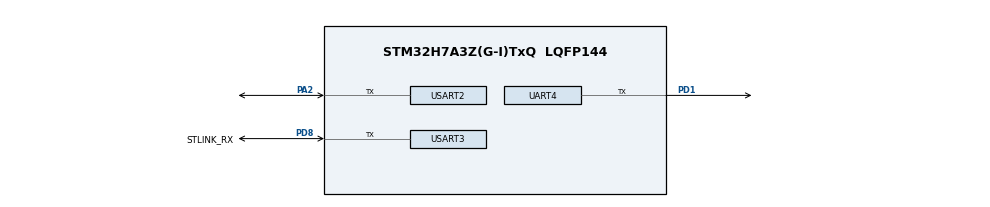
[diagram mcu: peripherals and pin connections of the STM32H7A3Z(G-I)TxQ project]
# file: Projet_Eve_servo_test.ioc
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Mcu.Family=STM32H7
Mcu.Name=STM32H7A3Z(G-I)TxQ
Mcu.Package=LQFP144
NVIC.PriorityGroup=NVIC_PRIORITYGROUP_4
PA2.GPIO_ModeDefaultOD=GPIO_MODE_AF_PP
PA2.GPIO_PuPd=GPIO_PULLUP
PA2.Mode=Half_duplex(single_wire_mode)
PA2.Signal=USART2_TX
PC14-OSC32_IN.GPIO_Label=OSC32_IN
PC14-OSC32_IN.Mode=LSE-External-Oscillator
PC14-OSC32_IN.Signal=RCC_OSC32_IN
PC15-OSC32_OUT.GPIO_Label=OSC32_OUT
PC15-OSC32_OUT.Mode=LSE-External-Oscillator
PC15-OSC32_OUT.Signal=RCC_OSC32_OUT
PD1.GPIO_ModeDefaultOD=GPIO_MODE_AF_OD
PD1.GPIO_PuPd=GPIO_PULLUP
PD1.GPIO_Speed=GPIO_SPEED_FREQ_VERY_HIGH
PD1.Mode=Half_duplex(single_wire_mode)
PD1.Signal=UART4_TX
PD8.GPIO_Label=STLINK_RX
PD8.GPIO_ModeDefaultOD=GPIO_MODE_AF_OD
PD8.GPIO_PuPd=GPIO_PULLUP
PD8.GPIO_Speed=GPIO_SPEED_FREQ_VERY_HIGH
PD8.Mode=Half_duplex(single_wire_mode)
PD8.Signal=USART3_TX
PD9.GPIO_Label=STLINK_TX
PD9.Signal=USART3_RX
PH0-OSC_IN.GPIO_Label=PH0-MCU
PH0-OSC_IN.Mode=HSE-External-Clock-Source
PH0-OSC_IN.Signal=RCC_OSC_IN
ProjectManager.HeapSize=0x200
ProjectManager.StackSize=0x400
ProjectManager.TargetToolchain=STM32CubeIDE
RCC.ADCFreq_Value=16125000
RCC.APB1Freq_Value=96000000
RCC.APB2Freq_Value=96000000
RCC.APB3Freq_Value=96000000
RCC.APB4Freq_Value=96000000
RCC.CortexFreq_Value=96000000
RCC.DIVM1=1
RCC.DIVM3=1
RCC.DIVN1=24
RCC.DIVN3=24
RCC.DIVQ1=4
RCC.HCLKFreq_Value=96000000
RCC.HSE_VALUE=8000000
RCC.PLLFRACN=0
RCC.PLLSourceVirtual=RCC_PLLSOURCE_HSE
RCC.PWR_Regulator_Voltage_Scale=PWR_REGULATOR_VOLTAGE_SCALE0
RCC.SYSCLKFreq_VALUE=96000000
RCC.SYSCLKSource=RCC_SYSCLKSOURCE_PLLCLK
RCC.SupplySource=PWR_DIRECT_SMPS_SUPPLY
RCC.USBCLockSelection=RCC_USBCLKSOURCE_HSI48
RCC.USBFreq_Value=48000000
UART4.BaudRate=57600
UART4.Mode=MODE_TX
USART2.BaudRate=57600
USART2.VirtualMode-Half_duplex(single_wire_mode)=VM_ASYNC
USART3.Mode=MODE_TX_RX
USART3.VirtualMode-Half_duplex(single_wire_mode)=VM_ASYNC
board=NUCLEO-H7A3ZI-Q

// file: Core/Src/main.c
/* USER CODE BEGIN Header */
/**
  ******************************************************************************
  * @file           : main.c
  * @brief          : Main program body
  ******************************************************************************
  * @attention
  *
  * Copyright (c) 2023 STMicroelectronics.
  * All rights reserved.
  *
  * This software is licensed under terms that can be found in the LICENSE file
  * in the root directory of this software component.
  * If no LICENSE file comes with this software, it is provided AS-IS.
  *
  ******************************************************************************
  */
/* USER CODE END Header */
#include "main.h"
#include "usart.h"
#include "gpio.h"

/* USER CODE BEGIN Includes */
#include <stdio.h>
#include <string.h>
#include <stdint.h>
#include "stm32h7xx.h"
#include "dyn2.h"
#include "constants.h"

/* USER CODE END Includes */

void SystemClock_Config(void);

int main(void)
{

  /* MCU Configuration--------------------------------------------------------*/

  /* Reset of all peripherals, Initializes the Flash interface and the Systick. */
  HAL_Init();

  /* Configure the system clock */
  SystemClock_Config();

  /* Initialize all configured peripherals */
  MX_GPIO_Init();
  MX_USART3_UART_Init();
  MX_UART4_Init();
  MX_USART2_UART_Init();
  /* USER CODE BEGIN 2 */

  MOTOR XL430_1 = {
      .model = XL430,
      .baudrate = 57600,
      .uart = huart4, // Assuming huart4 is already defined elsewhere
      .id = 1
  };

  MOTOR XL320_1 = {
      .model = XL320,
      .baudrate = 1000000,
      .uart = huart4, // Assuming huart4 is already defined elsewhere
      .id = 0xFE
  };
  //dyn2_torque(XL320_1, TORQUE_ON);
  //float angle = 0;
//  for(int i = 0;i<10;i++){
//	  dyn2_led(XL320_1,2);
//	  //dyn2_torque(XL320_1, TORQUE_ON);
//	  dyn2_position(XL320_1, angle);
//	  HAL_Delay(2000);
//	  dyn2_led(XL320_1,0);
//	  HAL_Delay(2000);
//	  angle +=45;
//
//
//  }
  	 dyn2_led(XL320_1, 2);
  	 //dyn2_torque(XL320_1, TORQUE_OFF);
  	 //dyn2_baudrate(XL320_1, 1);

  /* USER CODE END 2 */

  /* Infinite loop */
  /* USER CODE BEGIN WHILE */
  while (1){
	  //dyn2_position(XL430_1,90);
	  //HAL_Delay(1000);
	  //dyn2_led(XL320_1,LED_OFF);
	  //dyn2_position(XL430_1,0);

	  //HAL_Delay(1000);

    /* USER CODE END WHILE */

  }
}

void SystemClock_Config(void)
{
  RCC_OscInitTypeDef RCC_OscInitStruct = {0};
  RCC_ClkInitTypeDef RCC_ClkInitStruct = {0};

  /*AXI clock gating */
  RCC->CKGAENR = 0xFFFFFFFF;

  /** Supply configuration update enable
  */
  HAL_PWREx_ConfigSupply(PWR_DIRECT_SMPS_SUPPLY);

  /** Configure the main internal regulator output voltage
  */
  __HAL_PWR_VOLTAGESCALING_CONFIG(PWR_REGULATOR_VOLTAGE_SCALE0);

  while(!__HAL_PWR_GET_FLAG(PWR_FLAG_VOSRDY)) {}

  /** Initializes the RCC Oscillators according to the specified parameters
  * in the RCC_OscInitTypeDef structure.
  */
  RCC_OscInitStruct.OscillatorType = RCC_OSCILLATORTYPE_HSE;
  RCC_OscInitStruct.HSEState = RCC_HSE_BYPASS;
  RCC_OscInitStruct.PLL.PLLState = RCC_PLL_ON;
  RCC_OscInitStruct.PLL.PLLSource = RCC_PLLSOURCE_HSE;
  RCC_OscInitStruct.PLL.PLLM = 1;
  RCC_OscInitStruct.PLL.PLLN = 24;
  RCC_OscInitStruct.PLL.PLLP = 2;
  RCC_OscInitStruct.PLL.PLLQ = 4;
  RCC_OscInitStruct.PLL.PLLR = 2;
  RCC_OscInitStruct.PLL.PLLRGE = RCC_PLL1VCIRANGE_3;
  RCC_OscInitStruct.PLL.PLLVCOSEL = RCC_PLL1VCOWIDE;
  RCC_OscInitStruct.PLL.PLLFRACN = 0;
  if (HAL_RCC_OscConfig(&RCC_OscInitStruct) != HAL_OK)
  {
    Error_Handler();
  }

  /** Initializes the CPU, AHB and APB buses clocks
  */
  RCC_ClkInitStruct.ClockType = RCC_CLOCKTYPE_HCLK|RCC_CLOCKTYPE_SYSCLK
                              |RCC_CLOCKTYPE_PCLK1|RCC_CLOCKTYPE_PCLK2
                              |RCC_CLOCKTYPE_D3PCLK1|RCC_CLOCKTYPE_D1PCLK1;
  RCC_ClkInitStruct.SYSCLKSource = RCC_SYSCLKSOURCE_PLLCLK;
  RCC_ClkInitStruct.SYSCLKDivider = RCC_SYSCLK_DIV1;
  RCC_ClkInitStruct.AHBCLKDivider = RCC_HCLK_DIV1;
  RCC_ClkInitStruct.APB3CLKDivider = RCC_APB3_DIV1;
  RCC_ClkInitStruct.APB1CLKDivider = RCC_APB1_DIV1;
  RCC_ClkInitStruct.APB2CLKDivider = RCC_APB2_DIV1;
  RCC_ClkInitStruct.APB4CLKDivider = RCC_APB4_DIV1;

  if (HAL_RCC_ClockConfig(&RCC_ClkInitStruct, FLASH_LATENCY_2) != HAL_OK)
  {
    Error_Handler();
  }
}

void Error_Handler(void)
{
  __disable_irq();
  while (1)
  {
  }
}
